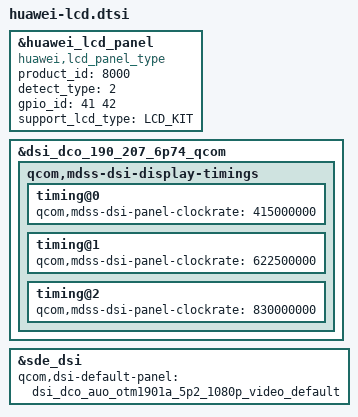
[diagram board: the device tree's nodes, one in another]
#include "../../../lcdkit3.0/dco/devkit_lcd_kit.dtsi"
&huawei_lcd_panel {
	compatible = "huawei,lcd_panel_type";
	/* auto_key_info @ name: product_id type: uint32 default: 0 */
	product_id = <8000>;
	detect_type = <2>;
	/* auto_key_info @ name: gpio_id[2] type: int default: 0 */
	gpio_id = <41 42>;
	support_lcd_type = "LCD_KIT";
};

&dsi_dco_190_207_6p74_qcom {
	qcom,mdss-dsi-display-timings {
		timing@0 {
			qcom,mdss-dsi-panel-clockrate = <415000000>;
		};
		timing@1 {
			qcom,mdss-dsi-panel-clockrate = <622500000>;
		};
		timing@2 {
			qcom,mdss-dsi-panel-clockrate = <830000000>;
		};
	};
};

&sde_dsi {
	qcom,dsi-default-panel = <&dsi_dco_auo_otm1901a_5p2_1080p_video_default>;
};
